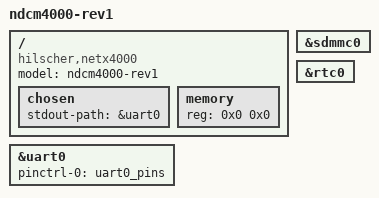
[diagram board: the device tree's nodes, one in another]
/*
* (C) Copyright 2018 Hilscher Gesellschaft fuer Systemautomation mbH
* http://www.hilscher.com
*
* This program is free software; you can redistribute it and/or
* modify it under the terms of the GNU General Public License as
* published by the Free Software Foundation; version 2 of
* the License.
*
* This program is distributed in the hope that it will be useful,
* but WITHOUT ANY WARRANTY; without even the implied warranty of
* MERCHANTABILITY or FITNESS FOR A PARTICULAR PURPOSE. See the
* GNU General Public License for more details.
*/

/dts-v1/;

#include "netx4000-common.dtsi"

/ {
	model = "ndcm4000-rev1";
	compatible = "hilscher,netx4000";

	chosen {
		stdout-path = &uart0;
	};

	memory {
		device_type = "memory";
		reg = <0x0 0x0>; /* will be filled by bootloader */
	};
};

&uart0 {
	status = "okay";
	pinctrl-names = "default";
	pinctrl-0 = <&uart0_pins>;
};

&sdmmc0 {
	status = "okay";
};

&rtc0 {
	status = "okay";
};
